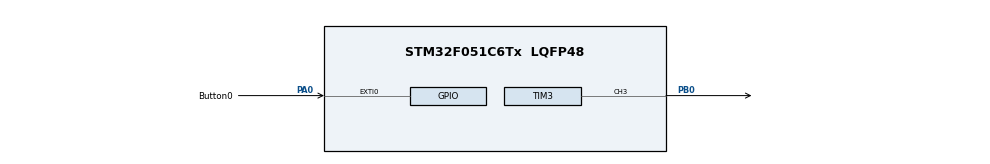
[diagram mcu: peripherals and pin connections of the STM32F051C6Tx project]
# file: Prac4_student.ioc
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Dma.Request0=TIM2_CH1
Dma.TIM2_CH1.0.Direction=DMA_MEMORY_TO_PERIPH
Dma.TIM2_CH1.0.Instance=DMA1_Channel5
Dma.TIM2_CH1.0.MemDataAlignment=DMA_MDATAALIGN_WORD
Dma.TIM2_CH1.0.MemInc=DMA_MINC_ENABLE
Dma.TIM2_CH1.0.Mode=DMA_CIRCULAR
Dma.TIM2_CH1.0.PeriphDataAlignment=DMA_PDATAALIGN_WORD
Dma.TIM2_CH1.0.PeriphInc=DMA_PINC_DISABLE
Dma.TIM2_CH1.0.Priority=DMA_PRIORITY_LOW
Mcu.Family=STM32F0
Mcu.Name=STM32F051C6Tx
Mcu.Package=LQFP48
NVIC.DMA1_Channel4_5_IRQn=true\:0\:0\:false\:false\:true\:false\:true\:true
PA0.GPIO_Label=Button0
PA0.GPIO_PuPd=GPIO_PULLUP
PA0.Signal=GPXTI0
PA13.Mode=Serial_Wire
PA13.Signal=SYS_SWDIO
PA14.Mode=Serial_Wire
PA14.Signal=SYS_SWCLK
PB0.Signal=S_TIM3_CH3
PF0-OSC_IN.Mode=HSE-External-Oscillator
PF0-OSC_IN.Signal=RCC_OSC_IN
PF1-OSC_OUT.Mode=HSE-External-Oscillator
PF1-OSC_OUT.Signal=RCC_OSC_OUT
ProjectManager.HeapSize=0x200
ProjectManager.StackSize=0x400
ProjectManager.TargetToolchain=STM32CubeIDE
SH.S_TIM3_CH3.0=TIM3_CH3,PWM Generation3 CH3
TIM2.AutoReloadPreload=TIM_AUTORELOAD_PRELOAD_ENABLE
TIM2.Channel-Output\ Compare1\ No\ Output=TIM_CHANNEL_1
TIM2.Period=100
TIM3.AutoReloadPreload=TIM_AUTORELOAD_PRELOAD_ENABLE
TIM3.Channel-PWM\ Generation3\ CH3=TIM_CHANNEL_3
TIM3.Period=1023
VP_TIM2_VS_ClockSourceINT.Mode=Internal
VP_TIM2_VS_no_output1.Mode=Output Compare1 No Output
VP_TIM3_VS_ClockSourceINT.Mode=Internal
board=custom

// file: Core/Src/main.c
/* USER CODE BEGIN Header */
/**
  ******************************************************************************
  * @file           : main.c
  * @brief          : Main program body
  ******************************************************************************
  * @attention
  *
  * Copyright (c) 2023 STMicroelectronics.
  * All rights reserved.
  *
  * This software is licensed under terms that can be found in the LICENSE file
  * in the root directory of this software component.
  * If no LICENSE file comes with this software, it is provided AS-IS.
  *
  ******************************************************************************
  */
/* USER CODE END Header */
#include "main.h"

/* USER CODE BEGIN Includes */
#include <stdio.h>
#include "stm32f0xx.h"
#include <lcd_stm32f0.c>
/* USER CODE END Includes */

/* USER CODE BEGIN PD */
// TODO: Add values for below variables
#define NS        // Number of samples in LUT
#define TIM2CLK   // STM Clock frequency
#define F_SIGNAL  // Frequency of output analog signal
/* USER CODE END PD */

TIM_HandleTypeDef htim2;
TIM_HandleTypeDef htim3;
DMA_HandleTypeDef hdma_tim2_ch1;

/* USER CODE BEGIN PV */
// TODO: Add code for global variables, including LUTs

uint32_t Sin_LUT[NS] = {};

uint32_t saw_LUT[NS] = {};

uint32_t triangle_LUT[NS] = {};

// TODO: Equation to calculate TIM2_Ticks
uint32_t TIM2_Ticks = 0; // How often to write new LUT value
uint32_t DestAddress = (uint32_t) &(TIM3->CCR3); // Write LUT TO TIM3->CCR3 to modify PWM duty cycle

/* USER CODE END PV */

void SystemClock_Config(void);
static void MX_GPIO_Init(void);
static void MX_DMA_Init(void);
static void MX_TIM2_Init(void);
static void MX_TIM3_Init(void);

/* USER CODE BEGIN PFP */
void EXTI0_1_IRQHandler(void);
/* USER CODE END PFP */

int main(void)
{

  /* MCU Configuration--------------------------------------------------------*/

  /* Reset of all peripherals, Initializes the Flash interface and the Systick. */
  HAL_Init();

  /* USER CODE BEGIN Init */
  init_LCD();
  /* USER CODE END Init */

  /* Configure the system clock */
  SystemClock_Config();

  /* Initialize all configured peripherals */
  MX_GPIO_Init();
  MX_DMA_Init();
  MX_TIM2_Init();
  MX_TIM3_Init();

  /* USER CODE BEGIN 2 */
  // TODO: Start TIM3 in PWM mode on channel 3

  // TODO: Start TIM2 in Output Compare (OC) mode on channel 1.

  // TODO: Start DMA in IT mode on TIM2->CH1; Source is LUT and Dest is TIM3->CCR3; start with Sine LUT

  // TODO: Write current waveform to LCD ("Sine")
  delay(3000);

  // TODO: Enable DMA (start transfer from LUT to CCR)

  /* USER CODE END 2 */

  /* Infinite loop */
  while (1)
  {

  }
}

void SystemClock_Config(void)
{
  LL_FLASH_SetLatency(LL_FLASH_LATENCY_0);
  while(LL_FLASH_GetLatency() != LL_FLASH_LATENCY_0)
  {
  }
  LL_RCC_HSI_Enable();

   /* Wait till HSI is ready */
  while(LL_RCC_HSI_IsReady() != 1)
  {

  }
  LL_RCC_HSI_SetCalibTrimming(16);
  LL_RCC_SetAHBPrescaler(LL_RCC_SYSCLK_DIV_1);
  LL_RCC_SetAPB1Prescaler(LL_RCC_APB1_DIV_1);
  LL_RCC_SetSysClkSource(LL_RCC_SYS_CLKSOURCE_HSI);

   /* Wait till System clock is ready */
  while(LL_RCC_GetSysClkSource() != LL_RCC_SYS_CLKSOURCE_STATUS_HSI)
  {

  }
  LL_SetSystemCoreClock(8000000);

   /* Update the time base */
  if (HAL_InitTick (TICK_INT_PRIORITY) != HAL_OK)
  {
    Error_Handler();
  }
}

static void MX_TIM2_Init(void)
{

  TIM_ClockConfigTypeDef sClockSourceConfig = {0};
  TIM_MasterConfigTypeDef sMasterConfig = {0};
  TIM_OC_InitTypeDef sConfigOC = {0};

  htim2.Instance = TIM2;
  htim2.Init.Prescaler = 0;
  htim2.Init.CounterMode = TIM_COUNTERMODE_UP;
  htim2.Init.Period = TIM2_Ticks - 1;
  htim2.Init.ClockDivision = TIM_CLOCKDIVISION_DIV1;
  htim2.Init.AutoReloadPreload = TIM_AUTORELOAD_PRELOAD_ENABLE;
  if (HAL_TIM_Base_Init(&htim2) != HAL_OK)
  {
    Error_Handler();
  }
  sClockSourceConfig.ClockSource = TIM_CLOCKSOURCE_INTERNAL;
  if (HAL_TIM_ConfigClockSource(&htim2, &sClockSourceConfig) != HAL_OK)
  {
    Error_Handler();
  }
  if (HAL_TIM_OC_Init(&htim2) != HAL_OK)
  {
    Error_Handler();
  }
  sMasterConfig.MasterOutputTrigger = TIM_TRGO_RESET;
  sMasterConfig.MasterSlaveMode = TIM_MASTERSLAVEMODE_DISABLE;
  if (HAL_TIMEx_MasterConfigSynchronization(&htim2, &sMasterConfig) != HAL_OK)
  {
    Error_Handler();
  }
  sConfigOC.OCMode = TIM_OCMODE_TIMING;
  sConfigOC.Pulse = 0;
  sConfigOC.OCPolarity = TIM_OCPOLARITY_HIGH;
  sConfigOC.OCFastMode = TIM_OCFAST_DISABLE;
  if (HAL_TIM_OC_ConfigChannel(&htim2, &sConfigOC, TIM_CHANNEL_1) != HAL_OK)
  {
    Error_Handler();
  }

}

static void MX_TIM3_Init(void)
{

  TIM_ClockConfigTypeDef sClockSourceConfig = {0};
  TIM_MasterConfigTypeDef sMasterConfig = {0};
  TIM_OC_InitTypeDef sConfigOC = {0};

  htim3.Instance = TIM3;
  htim3.Init.Prescaler = 0;
  htim3.Init.CounterMode = TIM_COUNTERMODE_UP;
  htim3.Init.Period = 1023;
  htim3.Init.ClockDivision = TIM_CLOCKDIVISION_DIV1;
  htim3.Init.AutoReloadPreload = TIM_AUTORELOAD_PRELOAD_ENABLE;
  if (HAL_TIM_Base_Init(&htim3) != HAL_OK)
  {
    Error_Handler();
  }
  sClockSourceConfig.ClockSource = TIM_CLOCKSOURCE_INTERNAL;
  if (HAL_TIM_ConfigClockSource(&htim3, &sClockSourceConfig) != HAL_OK)
  {
    Error_Handler();
  }
  if (HAL_TIM_PWM_Init(&htim3) != HAL_OK)
  {
    Error_Handler();
  }
  sMasterConfig.MasterOutputTrigger = TIM_TRGO_RESET;
  sMasterConfig.MasterSlaveMode = TIM_MASTERSLAVEMODE_DISABLE;
  if (HAL_TIMEx_MasterConfigSynchronization(&htim3, &sMasterConfig) != HAL_OK)
  {
    Error_Handler();
  }
  sConfigOC.OCMode = TIM_OCMODE_PWM1;
  sConfigOC.Pulse = 0;
  sConfigOC.OCPolarity = TIM_OCPOLARITY_HIGH;
  sConfigOC.OCFastMode = TIM_OCFAST_DISABLE;
  if (HAL_TIM_PWM_ConfigChannel(&htim3, &sConfigOC, TIM_CHANNEL_3) != HAL_OK)
  {
    Error_Handler();
  }
  HAL_TIM_MspPostInit(&htim3);

}

static void MX_DMA_Init(void)
{

  /* DMA controller clock enable */
  __HAL_RCC_DMA1_CLK_ENABLE();

  /* DMA interrupt init */
  /* DMA1_Channel4_5_IRQn interrupt configuration */
  HAL_NVIC_SetPriority(DMA1_Channel4_5_IRQn, 0, 0);
  HAL_NVIC_EnableIRQ(DMA1_Channel4_5_IRQn);

}

static void MX_GPIO_Init(void)
{
  LL_EXTI_InitTypeDef EXTI_InitStruct = {0};

  /* GPIO Ports Clock Enable */
  LL_AHB1_GRP1_EnableClock(LL_AHB1_GRP1_PERIPH_GPIOF);
  LL_AHB1_GRP1_EnableClock(LL_AHB1_GRP1_PERIPH_GPIOA);
  LL_AHB1_GRP1_EnableClock(LL_AHB1_GRP1_PERIPH_GPIOB);

  /**/
  LL_SYSCFG_SetEXTISource(LL_SYSCFG_EXTI_PORTA, LL_SYSCFG_EXTI_LINE0);

  /**/
  LL_GPIO_SetPinPull(Button0_GPIO_Port, Button0_Pin, LL_GPIO_PULL_UP);

  /**/
  LL_GPIO_SetPinMode(Button0_GPIO_Port, Button0_Pin, LL_GPIO_MODE_INPUT);

  /**/
  EXTI_InitStruct.Line_0_31 = LL_EXTI_LINE_0;
  EXTI_InitStruct.LineCommand = ENABLE;
  EXTI_InitStruct.Mode = LL_EXTI_MODE_IT;
  EXTI_InitStruct.Trigger = LL_EXTI_TRIGGER_RISING;
  LL_EXTI_Init(&EXTI_InitStruct);

/* USER CODE BEGIN MX_GPIO_Init_2 */
  HAL_NVIC_SetPriority(EXTI0_1_IRQn, 0, 0);
  HAL_NVIC_EnableIRQ(EXTI0_1_IRQn);
/* USER CODE END MX_GPIO_Init_2 */
}

/* USER CODE BEGIN 4 */
void EXTI0_1_IRQHandler(void)
{
	// TODO: Debounce using HAL_GetTick()

	// TODO: Disable DMA transfer and abort IT, then start DMA in IT mode with new LUT and re-enable transfer
	// HINT: Consider using C's "switch" function to handle LUT changes

	HAL_GPIO_EXTI_IRQHandler(Button0_Pin); // Clear interrupt flags
}
/* USER CODE END 4 */

void Error_Handler(void)
{
  __disable_irq();
  while (1)
  {
  }
}
